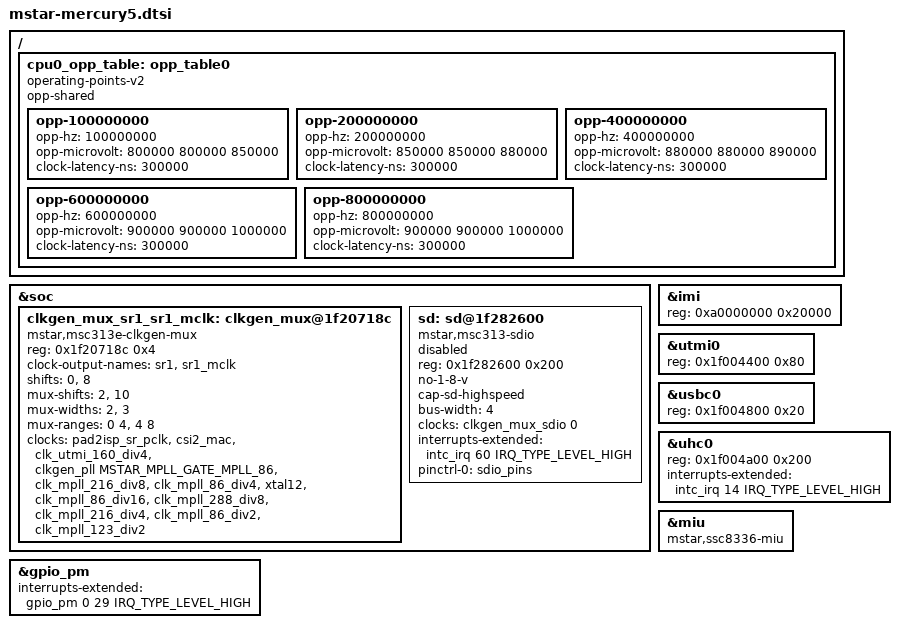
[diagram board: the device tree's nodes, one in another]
// SPDX-License-Identifier: GPL-2.0-or-later
/*
 * Copyright (c) 2020 thingy.jp.
 * Author: Daniel Palmer <daniel@thingy.jp>
 */

#include "mstar-v7.dtsi"

/ {
	cpu0_opp_table: opp_table0 {
		compatible = "operating-points-v2";
		opp-shared;

		opp-100000000 {
			opp-hz = /bits/ 64 <100000000>;
			opp-microvolt = <800000 800000 850000>;
			clock-latency-ns = <300000>;
		};

		opp-200000000 {
			opp-hz = /bits/ 64 <200000000>;
			opp-microvolt = <850000 850000 880000>;
			clock-latency-ns = <300000>;
		};

		opp-400000000 {
			opp-hz = /bits/ 64 <400000000>;
			opp-microvolt = <880000 880000 890000>;
			clock-latency-ns = <300000>;
		};
		opp-600000000 {
			opp-hz = /bits/ 64 <600000000>;
			opp-microvolt = <900000 900000 1000000>;
			clock-latency-ns = <300000>;
		};

		opp-800000000 {
			opp-hz = /bits/ 64 <800000000>;
			opp-microvolt = <900000 900000 1000000>;
			clock-latency-ns = <300000>;
		};
	};
};

&soc {
	/*
		m5 clkgens
		1f207164 - mipi tx csi

	*/

	/* guess! */
	clkgen_mux_sr1_sr1_mclk: clkgen_mux@1f20718c {
		compatible = "mstar,msc313e-clkgen-mux";
		reg = <0x1f20718c 0x4>;
		#clock-cells = <1>;
		clock-output-names = "sr1", "sr1_mclk";
		shifts = <0>, <8>;
		mux-shifts = <2>, <10>;
		mux-widths = <2>, <3>;
		mux-ranges = <0 4>, <4 8>;
		clocks =
		/* sr */
		<&pad2isp_sr_pclk>,
		<&csi2_mac>,
		<&clk_utmi_160_div4>,
		<&clkgen_pll MSTAR_MPLL_GATE_MPLL_86>,
		/* sr_mclk */
		<&clk_mpll_216_div8>,
		<&clk_mpll_86_div4>,
		<&xtal12>,
		<&clk_mpll_86_div16>,
		<&clk_mpll_288_div8>,
		<&clk_mpll_216_div4>,
		<&clk_mpll_86_div2>,
		<&clk_mpll_123_div2>;
	};

	sd: sd@1f282600 {
		compatible = "mstar,msc313-sdio";
		reg = <0x1f282600 0x200>;
		no-1-8-v;
		cap-sd-highspeed;
		bus-width = <4>;
		clocks = <&clkgen_mux_sdio 0>;
		interrupts-extended = <&intc_irq 60 IRQ_TYPE_LEVEL_HIGH>;
		pinctrl-names = "default";
		pinctrl-0 = <&sdio_pins>;
		status = "disabled";
	};
};

&imi {
	reg = <0xa0000000 0x20000>;
};

&utmi0 {
	reg = <0x1f004400 0x80>;
};

&usbc0 {
	reg = <0x1f004800 0x20>;
};

&uhc0 {
	reg = <0x1f004a00 0x200>;
	interrupts-extended = <&intc_irq 14 IRQ_TYPE_LEVEL_HIGH>;
};

&gpio_pm {
	interrupt-names = "pm_spi_do", "pm_sd_sdz";
	interrupts-extended = <&gpio_pm 0 29 IRQ_TYPE_LEVEL_HIGH>;
			      /*<&intc_fiq 23 IRQ_TYPE_LEVEL_HIGH>;*/
};

&miu {
	compatible = "mstar,ssc8336-miu";
};
